# HSI_DMA_CHANNELS register map
Vendor: Texas Instruments
Peripheral module from a debugger description file (folder omap4430).
Registers are 32-bit, access per field, reset 0x0 unless marked. A register's access mark holds for its fields unless they carry their own. Offsets are as the file gives them; lines under a group give offsets from that group; [hi:lo] are bit positions; {n}, {i} and the like mark numbered series; 'fields as' and 'values as' point back to an identical list; <NAME> marks a mode.

## HSI_DMA_CHANNELS
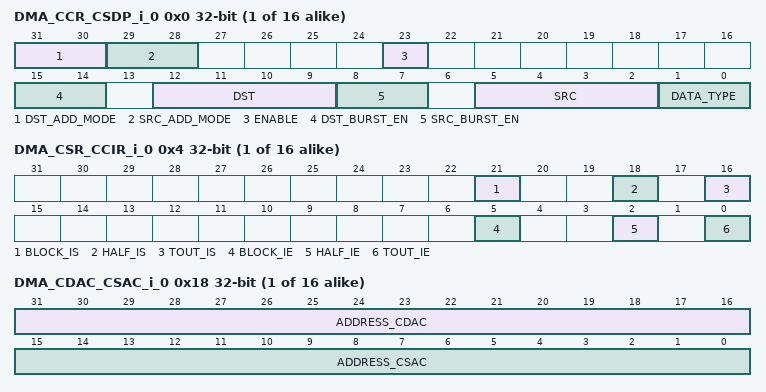
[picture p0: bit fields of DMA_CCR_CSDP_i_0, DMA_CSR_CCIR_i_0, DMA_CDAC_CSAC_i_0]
{0x0+0x40*i} DMA_CCR_CSDP_i_{i} (i=0..15) — Stores source and destination parameters and channel control bits
  [31:30] DST_ADD_MODE rw — Destination addressing mode
    0=constant address; 1=post increment address
  [29:28] SRC_ADD_MODE rw — Source addressing mode
    0=constant address; 1=post increment address
  [23] ENABLE rw — Logical channel enable
    0=transfer stops and is reset; 1=transfer is enabled. Automatically cleared by hardware once transfer is finished
  [15:14] DST_BURST_EN rw — Destination burst enable
    0=single access; 1=single access; 3=burst 8x32 bits (not implemented); 2=burst 4x32 bits
  [12:9] DST rw — Transfer destination
    8=Transfer to Memory port; 9=Transfer to Peripheral port
  [8:7] SRC_BURST_EN rw — Source burst enable
    values as DST_BURST_EN
  [5:2] SRC rw — Transfer source
    8=Transfer From Memory port; 9=Transfer From Peripheral port
  [1:0] DATA_TYPE rw — Defines data typesImplemented bitfield but not used
{0x4+0x40*i} DMA_CSR_CCIR_i_{i} (i=0..15) — Interrupt enable and status registerInterrupt flag fields will be cleared through read access using the following byteenable values:0xC0xF
  [21] BLOCK_IS ro — Block transferred
    1=BLOCK_IS_1_r (block transferred); 0=BLOCK_IS_0_r (no event)
  [18] HALF_IS ro — Half block reached
    1=HALF_IS_1_r (half block transferred); 0=HALF_IS_0_r (no event)
  [16] TOUT_IS ro — Time-out overflow event
    1=TOUT_IS_1_r (time-out occurred); 0=TOUT_IS_0_r (no event)
  [5] BLOCK_IE rw — Interrupt is sent when a full block is transferred
    0=no interrupt; 1=interrupt enable
  [2] HALF_IE rw — Interrupt is sent when a half block is transferred
    0=no interrupt; 1=interrupt enable
  [0] TOUT_IE rw — Interrupt is sent when a time-out overflow occurs
    0=no interrupt; 1=interrupt enable
{0x8+0x40*i} DMA_CSSA_i_{i} rw (i=0..15) — Stores source start addressIf the transfer configured from memory port all bits are taken into account as an address,if the transfer configured from peripheral port the lower four bits will determine the FIFO ID.
  [31:0] ADDR — source start address
{0xC+0x40*i} DMA_CDSA_i_{i} rw (i=0..15) — Stores destination start addressIf the transfer configured to memory port all bits are taken into account as an address,if the transfer configured to peripheral port the lower four bits will determine the FIFO ID.
  [31:0] ADDR — destination start address
{0x10+0x40*i} DMA_CEN_i_{i} (i=0..15) — Stores the number of 4 byte words in a DMA data block. Max is 65536.
  [15:0] SIZE rw — Number of elements in a block. Max is 65536.
{0x18+0x40*i} DMA_CDAC_CSAC_i_{i} ro (i=0..15) — Monitors the progress of DMA transfer, by storing the 16-bit counter address for source and destination.
  [31:16] ADDRESS_CDAC — Destination address
  [15:0] ADDRESS_CSAC — Source address
